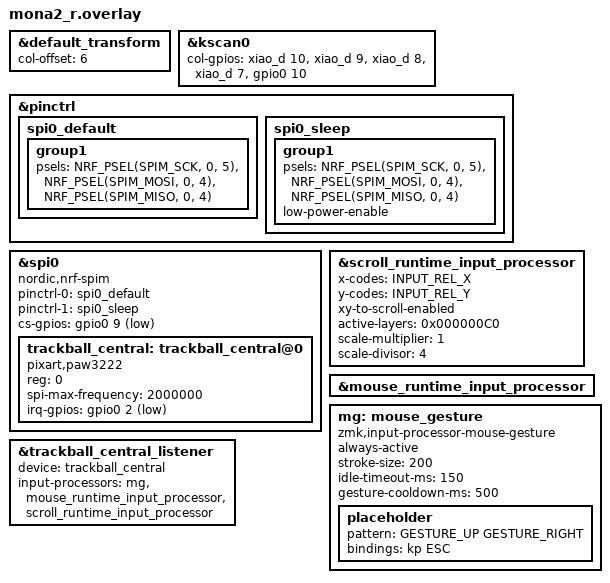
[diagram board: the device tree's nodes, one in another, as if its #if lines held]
#include "mona2.dtsi"
/* mona2.dtsi 内で RC(row,col) のマトリクス展開が終わった後に include する
   (runtime-input-processor.dtsi が modifiers.h 経由で RC(keycode) を再定義するため) */
#include <input/processors/runtime-input-processor.dtsi>
#include <input/processors.dtsi>
#include <zephyr/dt-bindings/input/input-event-codes.h>
#include <dt-bindings/zmk/mouse-gesture.h>

&default_transform {
    col-offset = <6>;
};

&kscan0 {
    col-gpios
        = <&xiao_d 10 GPIO_ACTIVE_HIGH>
        , <&xiao_d 9 GPIO_ACTIVE_HIGH>
        , <&xiao_d 8 GPIO_ACTIVE_HIGH>
        , <&xiao_d 7 GPIO_ACTIVE_HIGH>
        , <&gpio0 10 GPIO_ACTIVE_HIGH>
        ;
};

&pinctrl {
    spi0_default: spi0_default {
        group1 {
            psels = <NRF_PSEL(SPIM_SCK, 0, 5)>,
                <NRF_PSEL(SPIM_MOSI, 0, 4)>,
                <NRF_PSEL(SPIM_MISO, 0, 4)>;
        };
    };

    spi0_sleep: spi0_sleep {
        group1 {
            psels = <NRF_PSEL(SPIM_SCK, 0, 5)>,
                <NRF_PSEL(SPIM_MOSI, 0, 4)>,
                <NRF_PSEL(SPIM_MISO, 0, 4)>;
            low-power-enable;
        };
    };
};

&spi0 {
    status = "okay";
    compatible = "nordic,nrf-spim";
    pinctrl-0 = <&spi0_default>;
    pinctrl-1 = <&spi0_sleep>;
    pinctrl-names = "default", "sleep";
    cs-gpios = <&gpio0 9 GPIO_ACTIVE_LOW>;

    trackball_central: trackball_central@0 {
        status = "okay";
#ifdef CONFIG_TRACKBALL_PAW3222
        compatible = "pixart,paw3222";
        reg = <0>;
        spi-max-frequency = <2000000>;
        irq-gpios = <&gpio0 2 (GPIO_ACTIVE_LOW | GPIO_PULL_UP)>;
#else /* default: PMW3610 */
        compatible = "pixart,pmw3610";
        reg = <0>;
        spi-max-frequency = <2000000>;
        irq-gpios = <&gpio0 2 (GPIO_ACTIVE_LOW | GPIO_PULL_UP)>;
        cpi = <600>;
        //swap-xy;
        invert-x; //COROPIT版ではコメントアウトを外す
        //invert-y; //この個体ではY軸は反転不要だったためコメントアウト
        evt-type = <INPUT_EV_REL>;
        x-input-code = <INPUT_REL_X>;
        y-input-code = <INPUT_REL_Y>;
#endif
    };
};

/* ─────────────────────────────────────────────────────────────
   scroll_runtime_input_processor をスクロール変換器として上書き
   デフォルトでは x-codes=HWHEEL / y-codes=WHEEL で
   「すでにスクロールイベントになっているもの」しか処理しない設定。
   トラックボールの生イベント(REL_X/Y) を受け取って
   xy-to-scroll-enabled でスクロールに変換する形に切替える。

   ・active-layers : デフォルトのスクロールレイヤー bitmask
       bit6=scroll_win, bit7=scroll_mac → 0x000000C0
     DYA Studio から変更可能(再ビルド不要)
   ・xy-to-scroll-enabled : REL_X→HWHEEL, REL_Y→WHEEL に変換
     こちらも Studio から ON/OFF 可能
   ────────────────────────────────────────────────────── */
&scroll_runtime_input_processor {
    x-codes = <INPUT_REL_X>;
    y-codes = <INPUT_REL_Y>;
    xy-to-scroll-enabled;
    active-layers = <0x000000C0>; /* layer6 + layer7 */
    scale-multiplier = <1>;
    scale-divisor = <4>; /* スクロール速度。大きいほど遅い。Studioで調整可 */

    /* 軸ロック(縦のみ等)が欲しければ AXIS_SNAP_MODE_Y を初期値に */
    /* #include <dt-bindings/zmk/runtime_input_processor.h> 必要 */
    /* axis-snap-mode = <2>; */
    /* axis-snap-threshold = <100>; */
};

/* マウス用は全レイヤーで有効 (active-layers = 0 がデフォルト) */
&mouse_runtime_input_processor {
    /* 例: マウス感度初期値を Studio から調整したいだけならここで触らなくてOK */
};

/* ─────────────────────────────────────────────────────────────
   kot149 mouse-gesture input processor (Phase 5)

   - always-active で常時 ON
   - placeholder gesture を 1 個定義 (NUM_DTS_DEFAULTS > 0 にして
     seed_from_dts() を機能させるため)
   - 起動後は RPC (`mg_cli` / DYA Studio Web UI) で trie 上書き可
   - stroke-size, idle-timeout-ms 等は RPC の Settings からも変更可
   ────────────────────────────────────────────────────── */
mg: mouse_gesture {
    compatible = "zmk,input-processor-mouse-gesture";
    #input-processor-cells = <0>;
    always-active;
    stroke-size = <200>;
    idle-timeout-ms = <150>;
    gesture-cooldown-ms = <500>;

    placeholder {
        pattern = <GESTURE_UP GESTURE_RIGHT>;
        bindings = <&kp ESC>;
    };
};

/* ─────────────────────────────────────────────────────────────
   入力リスナー
   メインチェーン: mg(ジェスチャ判定) → mouse(感度) → scroll
   ・mg は raw event を最初に見てパターン蓄積。発火時に behavior 実行
   ・mouse は全レイヤーで走る(scale/invert を適用)
   ・scroll は active-layers のレイヤーでのみ走る
     → 該当レイヤー以外では素通しでマウスとして動作
   ────────────────────────────────────────────────────── */
&trackball_central_listener {
    status = "okay";
    device = <&trackball_central>;
    input-processors = <&mg &mouse_runtime_input_processor &scroll_runtime_input_processor>;
};
